# RA6M2 register map
Vendor: Renesas Electronics Corporation; Series: RA6; File version: 1.1
CPU: CM4 r0p1, little endian, MPU, FPU, VTOR, 4 interrupt priority bits
Registers are 8-bit, read-write, reset 0x0 unless marked. A register's access mark holds for its fields unless they carry their own. Offsets are from the block's base; [hi:lo] are bit positions; lines under a group give offsets from that group; {n}, {i} and the like mark numbered series; 'fields as' and 'values as' point back to an identical list.

## SMPU — Bus Slave MPU
Base 0x40000C00
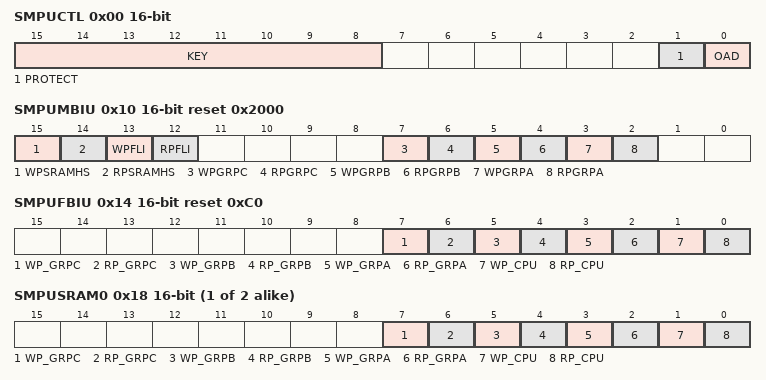
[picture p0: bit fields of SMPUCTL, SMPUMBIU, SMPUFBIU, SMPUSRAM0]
0x00 SMPUCTL 16-bit — Slave MPU Control Register
  [15:8] KEY wo — Key Code This bit is used to enable or disable rewriting of the PROTECT and OAD bit.
    165=Writing to the PROTECT and OAD bit is valid, when the KEY bits are written 0xA5; other=others (Writing to the PROTECT and OAD bit is invalid.)
  [1] PROTECT — Protection of register
    0=All Bus Slave register writing is possible; 1=All Bus Slave register writing is protected. Read is possible.
  [0] OAD — Master Group enable
    0=Non-maskable interrupt; 1=Internal reset
0x10 SMPUMBIU 16-bit reset 0x2000 — Access Control Register for MBIU
  [15] WPSRAMHS — SRAMHS Write Protection
    0=Memory protection for SRAMHS writes from master group A, B, and C disabled; 1=Memory protection for SRAMHS writes from master group A, B, and C enabled
  [14] RPSRAMHS — SRAMHS Read Protection
    0=Memory protection for SRAMHS reads from master group A, B, and C disabled; 1=Memory protection for SRAMHS reads from master group A, B, and C enabled
  [13] WPFLI — Code Flash Memory Write Protection (Note: This bit is read as 1. The write value should be 1.)
    0=Setting prohibited; 1=Memory protection for code flash memory writes from master group A, B, and C enabled
  [12] RPFLI — Code Flash Memory Read Protection
    0=Memory protection for code flash memory reads from master group A, B, and C disabled; 1=Memory protection for code flash memory reads from master group A, B, and C enabled
  [7] WPGRPC — Master Group C Write protection
    0=Memory protection for master group C writes disabled; 1=Memory protection for master group C writes enabled
  [6] RPGRPC — Master Group C Read protection
    0=Memory protection for master group C reads disabled; 1=Memory protection for master group C reads enabled
  [5] WPGRPB — Master Group B Write protection
    0=Memory protection for master group B writes disabled; 1=Memory protection for master group B writes enabled
  [4] RPGRPB — Master Group B Read protection
    0=Memory protection for master group B reads disabled; 1=Memory protection for master group B reads enabled
  [3] WPGRPA — Master Group A Write protection
    0=Memory protection for master group A writes disabled; 1=Memory protection for master group A writes enabled
  [2] RPGRPA — Master Group A Read protection
    0=Memory protection for master group A reads disabled; 1=Memory protection for master group A reads enabled
0x14 SMPUFBIU 16-bit reset 0xC0 — Access Control Register for FBIU
  [7] WP_GRPC — Master Group C Write protection
    0=Setting prohibited; 1=Master group C write of memory protection is enabled. The write value should always be 1.
  [6] RP_GRPC — Master Group C Read protection
    0=Setting prohibited; 1=Master group C read of memory protection is enabled. The write value should always be 1.
  [5] WP_GRPB — Master Group B Write protection
    0=Master group B write of memory protection is disabled; 1=Master group B write of memory protection is enabled
  [4] RP_GRPB — Master Group B Read protection
    0=Master group B read of memory protection is disabled; 1=Master group B read of memory protection is enabled
  [3] WP_GRPA — Master Group A Write protection
    0=Master group A write of memory protection is disabled; 1=Master group A write of memory protection is enabled
  [2] RP_GRPA — Master Group A Read protection
    0=Master group A read of memory protection is disabled; 1=Master group A read of memory protection is enabled
  [1] WP_CPU — CPU Write protection
    0=CPU write of memory protection is disabled; 1=CPU write of memory protection is enabled
  [0] RP_CPU — CPU Read protection
    0=CPU read of memory protection is disabled; 1=CPU read of memory protection is enabled
{0x18+4i} SMPUSRAM{i} (i=0..1) 16-bit — Access Control Register for SRAM{i}
  [7] WP_GRPC — Master Group C Write protection
    0=Master group C write of memory protection is disabled; 1=Master group C write of memory protection is enabled
  [6] RP_GRPC — Master Group C Read protection
    0=Master group C read of memory protection is disabled; 1=Master group C read of memory protection is enabled
  [5] WP_GRPB — Master Group B Write protection
    values as SMPUFBIU.WP_GRPB
  [4] RP_GRPB — Master Group B Read protection
    values as SMPUFBIU.RP_GRPB
  [3] WP_GRPA — Master Group A Write protection
    values as SMPUFBIU.WP_GRPA
  [2] RP_GRPA — Master Group A Read protection
    values as SMPUFBIU.RP_GRPA
  [1] WP_CPU — CPU Write protection
    values as SMPUFBIU.WP_CPU
  [0] RP_CPU — CPU Read protection
    values as SMPUFBIU.RP_CPU
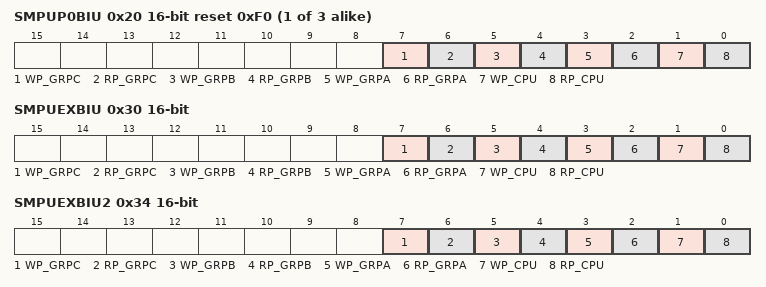
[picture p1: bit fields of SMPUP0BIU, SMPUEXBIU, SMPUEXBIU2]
0x20 SMPUP{x}BIU (x=0,2,6; step 0x4) 16-bit reset 0xF0 — Access Control Register for P{x}BIU
  [7] WP_GRPC — Master Group C Write protection
    values as SMPUFBIU.WP_GRPC
  [6] RP_GRPC — Master Group C Read protection
    values as SMPUFBIU.RP_GRPC
  [5] WP_GRPB — Master Group B Write protection
    0=Setting prohibited; 1=Master group B write of memory protection is enabled. The write value should always be 1.
  [4] RP_GRPB — Master Group B Read protection
    0=Setting prohibited; 1=Master group B read of memory protection is enabled. The write value should always be 1.
  [3] WP_GRPA — Master Group A Write protection
    values as SMPUFBIU.WP_GRPA
  [2] RP_GRPA — Master Group A Read protection
    values as SMPUFBIU.RP_GRPA
  [1] WP_CPU — CPU Write protection
    values as SMPUFBIU.WP_CPU
  [0] RP_CPU — CPU Read protection
    values as SMPUFBIU.RP_CPU
0x30 SMPUEXBIU 16-bit — Access Control Register for EXBIU
  fields as SMPUSRAM0
0x34 SMPUEXBIU2 16-bit — Access Control Register for EXBIU2
  fields as SMPUSRAM0
